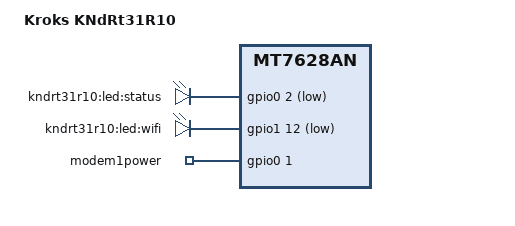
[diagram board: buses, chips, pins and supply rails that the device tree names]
#include "mt7628an_kroks_1eth.dtsi"

/ {
	compatible = "kroks,kndrt31r10", "mediatek,mt7628an-soc";
	model = "Kroks KNdRt31R10";

	aliases {
		led-boot = &led_status;
		led-failsafe = &led_status;
		led-running = &led_status;
		led-upgrade = &led_status;
	};

	leds {
		compatible = "gpio-leds";

		led_status: status {
			label = "kndrt31r10:led:status";
			gpios = <&gpio0 2 GPIO_ACTIVE_LOW>;
		};

		wifi {
			label = "kndrt31r10:led:wifi";
			gpios = <&gpio1 12 GPIO_ACTIVE_LOW>;
			linux,default-trigger = "phy0tpt";
		};
	};

	gpio_export {
		compatible = "gpio-export";
		#size-cells = <0>;

		modem1power {
			gpio-export,name = "modem1power";
			gpio-export,output = <1>;
			gpios = <&gpio0 1 GPIO_ACTIVE_HIGH>;
		};
	};
};

&state_default {
	gpio {
		ralink,group = "i2s", "wled_an";
		ralink,function = "gpio";
	};
};
